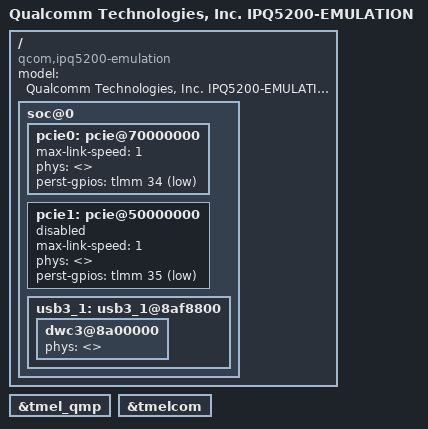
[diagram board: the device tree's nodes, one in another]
// SPDX-License-Identifier: GPL-2.0-only
/*
 * Copyright (c) Qualcomm Technologies, Inc. and/or its subsidiaries.
 */

/dts-v1/;

#include "ipq5200-u-boot.dtsi"

/ {
	model = "Qualcomm Technologies, Inc. IPQ5200-EMULATION";
	compatible = "qcom,ipq5200-emulation", "qcom,ipq5200";

	soc@0 {
		pcie0: pcie@70000000 {
			max-link-speed = <1>;
			phys = <>;
			phy-names = "";
			perst-gpios = <&tlmm 34 GPIO_ACTIVE_LOW>;
			status = "okay";
		};

		pcie1: pcie@50000000 {
			max-link-speed = <1>;
			phys = <>;
			phy-names = "";
			perst-gpios = <&tlmm 35 GPIO_ACTIVE_LOW>;
			status = "disabled";
		};

		usb3_1: usb3_1@8af8800 {
			status = "okay";
			dwc3@8a00000 {
				phys = <>;
				phy-names = "";
			};
		};
	};
};

&tmel_qmp {
	status = "okay";
};

&tmelcom {
	status = "okay";
};
